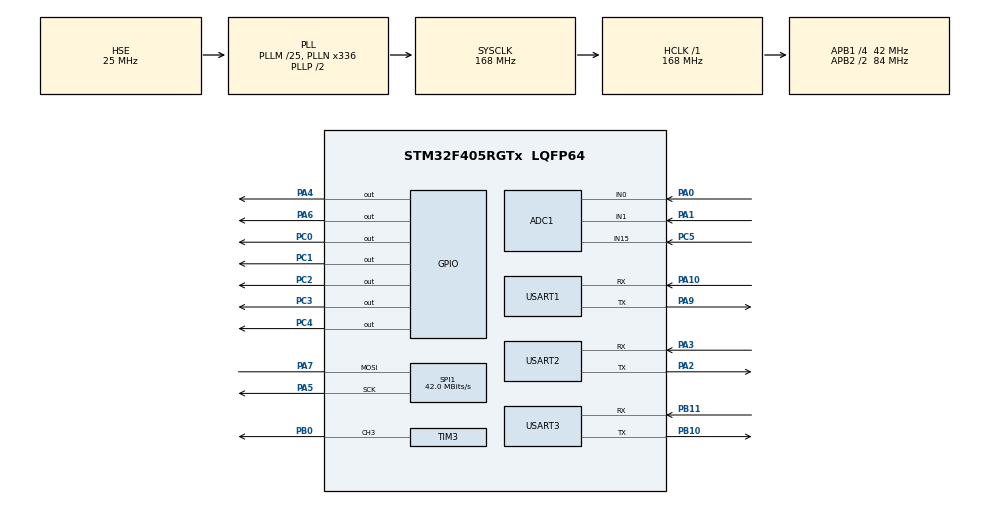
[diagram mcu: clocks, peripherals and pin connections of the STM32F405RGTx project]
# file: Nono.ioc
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ADC1.Channel-0\#ChannelRegularConversion=ADC_CHANNEL_0
ADC1.Channel-10\#ChannelRegularConversion=ADC_CHANNEL_TEMPSENSOR
ADC1.Channel-8\#ChannelRegularConversion=ADC_CHANNEL_1
ADC1.Channel-9\#ChannelRegularConversion=ADC_CHANNEL_15
ADC1.DataAlign=ADC_DATAALIGN_RIGHT
ADC1.InjNumberOfConversion=0
ADC1.NbrOfConversion=4
ADC1.NbrOfConversionFlag=1
ADC1.Rank-0\#ChannelRegularConversion=1
ADC1.Rank-10\#ChannelRegularConversion=4
ADC1.Rank-8\#ChannelRegularConversion=2
ADC1.Rank-9\#ChannelRegularConversion=3
ADC1.SamplingTime-0\#ChannelRegularConversion=ADC_SAMPLETIME_3CYCLES
ADC1.SamplingTime-10\#ChannelRegularConversion=ADC_SAMPLETIME_3CYCLES
ADC1.SamplingTime-8\#ChannelRegularConversion=ADC_SAMPLETIME_3CYCLES
ADC1.SamplingTime-9\#ChannelRegularConversion=ADC_SAMPLETIME_3CYCLES
ADC1.master=1
Dma.ADC1.0.Direction=DMA_PERIPH_TO_MEMORY
Dma.ADC1.0.FIFOMode=DMA_FIFOMODE_DISABLE
Dma.ADC1.0.Instance=DMA2_Stream0
Dma.ADC1.0.MemDataAlignment=DMA_MDATAALIGN_HALFWORD
Dma.ADC1.0.MemInc=DMA_MINC_ENABLE
Dma.ADC1.0.Mode=DMA_NORMAL
Dma.ADC1.0.PeriphDataAlignment=DMA_PDATAALIGN_HALFWORD
Dma.ADC1.0.PeriphInc=DMA_PINC_DISABLE
Dma.ADC1.0.Priority=DMA_PRIORITY_LOW
Dma.Request0=ADC1
FREERTOS.Tasks01=Main,40,256,StartMainTask,Default,NULL,Dynamic,NULL,NULL;LED,24,128,StartLED,Default,NULL,Dynamic,NULL,NULL
Mcu.Family=STM32F4
Mcu.Name=STM32F405RGTx
Mcu.Package=LQFP64
NVIC.DMA2_Stream0_IRQn=true\:5\:0\:false\:false\:true\:true\:false\:true\:true
NVIC.PriorityGroup=NVIC_PRIORITYGROUP_4
NVIC.TIM1_UP_TIM10_IRQn=true\:15\:0\:false\:false\:true\:false\:false\:true\:true
NVIC.TimeBase=TIM1_UP_TIM10_IRQn
NVIC.TimeBaseIP=TIM1
NVIC.USART1_IRQn=true\:5\:0\:false\:false\:true\:true\:true\:true\:true
NVIC.USART2_IRQn=true\:5\:0\:false\:false\:true\:true\:true\:true\:true
NVIC.USART3_IRQn=true\:5\:0\:false\:false\:true\:true\:true\:true\:true
PA0-WKUP.Signal=ADCx_IN0
PA1.Signal=ADCx_IN1
PA10.Mode=Asynchronous
PA10.Signal=USART1_RX
PA13.Mode=Serial_Wire
PA13.Signal=SYS_JTMS-SWDIO
PA14.Mode=Serial_Wire
PA14.Signal=SYS_JTCK-SWCLK
PA2.Mode=Asynchronous
PA2.Signal=USART2_TX
PA3.Mode=Asynchronous
PA3.Signal=USART2_RX
PA4.Signal=GPIO_Output
PA5.Mode=Simplex_Bidirectional_Master
PA5.Signal=SPI1_SCK
PA6.Signal=GPIO_Output
PA7.Mode=Simplex_Bidirectional_Master
PA7.Signal=SPI1_MOSI
PA9.Mode=Asynchronous
PA9.Signal=USART1_TX
PB0.Signal=S_TIM3_CH3
PB10.Mode=Asynchronous
PB10.Signal=USART3_TX
PB11.Mode=Asynchronous
PB11.Signal=USART3_RX
PC0.Signal=GPIO_Output
PC1.Signal=GPIO_Output
PC2.Signal=GPIO_Output
PC3.Signal=GPIO_Output
PC4.Signal=GPIO_Output
PC5.Signal=ADCx_IN15
PH0-OSC_IN.Mode=HSE-External-Oscillator
PH0-OSC_IN.Signal=RCC_OSC_IN
PH1-OSC_OUT.Mode=HSE-External-Oscillator
PH1-OSC_OUT.Signal=RCC_OSC_OUT
ProjectManager.HeapSize=0x1200
ProjectManager.StackSize=0x1200
ProjectManager.TargetToolchain=MDK-ARM V5.32
RCC.48MHZClocksFreq_Value=84000000
RCC.AHBFreq_Value=168000000
RCC.APB1CLKDivider=RCC_HCLK_DIV4
RCC.APB1Freq_Value=42000000
RCC.APB1TimFreq_Value=84000000
RCC.APB2CLKDivider=RCC_HCLK_DIV2
RCC.APB2Freq_Value=84000000
RCC.APB2TimFreq_Value=168000000
RCC.CortexFreq_Value=168000000
RCC.HCLKFreq_Value=168000000
RCC.HSE_VALUE=25000000
RCC.HSI_VALUE=16000000
RCC.LSE_VALUE=32768
RCC.PLLM=25
RCC.PLLN=336
RCC.PLLSourceVirtual=RCC_PLLSOURCE_HSE
RCC.RCC_RTC_Clock_Source=RCC_RTCCLKSOURCE_HSE_DIV25
RCC.RCC_RTC_Clock_SourceVirtual=RCC_RTCCLKSOURCE_LSE
RCC.RCC_RTC_Clock_Source_FROM_HSE=RCC_RTCCLKSOURCE_HSE_DIV25
RCC.SYSCLKFreq_VALUE=168000000
RCC.SYSCLKSource=RCC_SYSCLKSOURCE_PLLCLK
RCC.VCOOutputFreq_Value=336000000
RTC.AsynchPrediv=100
RTC.Date=20
RTC.Hours=14
RTC.Minutes=30
RTC.SynchPrediv=10000
RTC.Year=25
SH.ADCx_IN0.0=ADC1_IN0,IN0
SH.ADCx_IN1.0=ADC1_IN1,IN1
SH.ADCx_IN15.0=ADC1_IN15,IN15
SH.S_TIM3_CH3.0=TIM3_CH3,PWM Generation3 CH3
SPI1.CalculateBaudRate=42.0 MBits/s
SPI1.Direction=SPI_DIRECTION_1LINE
SPI1.Mode=SPI_MODE_MASTER
SPI1.VirtualType=VM_MASTER
TIM3.Channel-PWM\ Generation3\ CH3=TIM_CHANNEL_3
TIM3.Period=100-1
TIM3.Prescaler=8400-1
USART1.VirtualMode=VM_ASYNC
USART2.VirtualMode=VM_ASYNC
USART3.VirtualMode=VM_ASYNC
VP_ADC1_TempSens_Input.Mode=IN-TempSens
VP_FREERTOS_VS_CMSIS_V2.Mode=CMSIS_V2
VP_RTC_VS_RTC_Activate.Mode=RTC_Enabled
VP_RTC_VS_RTC_Calendar.Mode=RTC_Calendar
VP_SYS_VS_tim1.Mode=TIM1
VP_TIM3_VS_ClockSourceINT.Mode=Internal
board=custom

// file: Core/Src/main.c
/* USER CODE BEGIN Header */
/**
 ******************************************************************************
 * @file           : main.c
 * @brief          : Main program body
 ******************************************************************************
 * @attention
 *
 * Copyright (c) 2025 STMicroelectronics.
 * All rights reserved.
 *
 * This software is licensed under terms that can be found in the LICENSE file
 * in the root directory of this software component.
 * If no LICENSE file comes with this software, it is provided AS-IS.
 *
 ******************************************************************************
 */
/* USER CODE END Header */
#include "main.h"
#include "cmsis_os.h"
#include "adc.h"
#include "dma.h"
#include "rtc.h"
#include "spi.h"
#include "tim.h"
#include "usart.h"
#include "gpio.h"

/* USER CODE BEGIN Includes */

#include "general_control.h"
#include "sensor.h"
/* USER CODE END Includes */

void SystemClock_Config(void);
void MX_FREERTOS_Init(void);

int main(void)
{

  /* MCU Configuration--------------------------------------------------------*/

  /* Reset of all peripherals, Initializes the Flash interface and the Systick. */
  HAL_Init();

  /* Configure the system clock */
  SystemClock_Config();

  /* Initialize all configured peripherals */
  MX_GPIO_Init();
  MX_DMA_Init();
  MX_ADC1_Init();
  MX_SPI1_Init();
  MX_TIM3_Init();
  MX_USART1_UART_Init();
  MX_RTC_Init();
  MX_USART2_UART_Init();
  MX_USART3_UART_Init();
  /* USER CODE BEGIN 2 */
  ALL_Init();
  /* USER CODE END 2 */

  /* Init scheduler */
  osKernelInitialize();

  /* Call init function for freertos objects (in cmsis_os2.c) */
  MX_FREERTOS_Init();

  /* Start scheduler */
  osKernelStart();

  /* We should never get here as control is now taken by the scheduler */

  /* Infinite loop */
  while (1)
  {

  }
}

void SystemClock_Config(void)
{
  RCC_OscInitTypeDef RCC_OscInitStruct = {0};
  RCC_ClkInitTypeDef RCC_ClkInitStruct = {0};

  /** Configure the main internal regulator output voltage
  */
  __HAL_RCC_PWR_CLK_ENABLE();
  __HAL_PWR_VOLTAGESCALING_CONFIG(PWR_REGULATOR_VOLTAGE_SCALE1);

  /** Initializes the RCC Oscillators according to the specified parameters
  * in the RCC_OscInitTypeDef structure.
  */
  RCC_OscInitStruct.OscillatorType = RCC_OSCILLATORTYPE_HSE;
  RCC_OscInitStruct.HSEState = RCC_HSE_ON;
  RCC_OscInitStruct.PLL.PLLState = RCC_PLL_ON;
  RCC_OscInitStruct.PLL.PLLSource = RCC_PLLSOURCE_HSE;
  RCC_OscInitStruct.PLL.PLLM = 25;
  RCC_OscInitStruct.PLL.PLLN = 336;
  RCC_OscInitStruct.PLL.PLLP = RCC_PLLP_DIV2;
  RCC_OscInitStruct.PLL.PLLQ = 4;
  if (HAL_RCC_OscConfig(&RCC_OscInitStruct) != HAL_OK)
  {
    Error_Handler();
  }

  /** Initializes the CPU, AHB and APB buses clocks
  */
  RCC_ClkInitStruct.ClockType = RCC_CLOCKTYPE_HCLK|RCC_CLOCKTYPE_SYSCLK
                              |RCC_CLOCKTYPE_PCLK1|RCC_CLOCKTYPE_PCLK2;
  RCC_ClkInitStruct.SYSCLKSource = RCC_SYSCLKSOURCE_PLLCLK;
  RCC_ClkInitStruct.AHBCLKDivider = RCC_SYSCLK_DIV1;
  RCC_ClkInitStruct.APB1CLKDivider = RCC_HCLK_DIV4;
  RCC_ClkInitStruct.APB2CLKDivider = RCC_HCLK_DIV2;

  if (HAL_RCC_ClockConfig(&RCC_ClkInitStruct, FLASH_LATENCY_5) != HAL_OK)
  {
    Error_Handler();
  }
}

void HAL_TIM_PeriodElapsedCallback(TIM_HandleTypeDef *htim)
{
  if (htim->Instance == TIM1)
  {
    HAL_IncTick();
  }
}

void Error_Handler(void)
{
  /* USER CODE BEGIN Error_Handler_Debug */
  /* User can add his own implementation to report the HAL error return state */
  __disable_irq();
  while (1)
  {
    HAL_GPIO_WritePin(GPIOC, GPIO_PIN_0, GPIO_PIN_SET);
    HAL_Delay(100);
    HAL_GPIO_WritePin(GPIOC, GPIO_PIN_0, GPIO_PIN_SET);
    HAL_Delay(100);
  }
  /* USER CODE END Error_Handler_Debug */
}

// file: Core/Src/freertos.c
/* USER CODE BEGIN Header */
/**
  ******************************************************************************
  * File Name          : freertos.c
  * Description        : Code for freertos applications
  ******************************************************************************
  * @attention
  *
  * Copyright (c) 2025 STMicroelectronics.
  * All rights reserved.
  *
  * This software is licensed under terms that can be found in the LICENSE file
  * in the root directory of this software component.
  * If no LICENSE file comes with this software, it is provided AS-IS.
  *
  ******************************************************************************
  */
/* USER CODE END Header */

#include "FreeRTOS.h"
#include "task.h"
#include "main.h"
#include "cmsis_os.h"

/* USER CODE BEGIN Includes */
#include "general_control.h"
#include "LED.h"
#include "expression.h"
#include "tim.h"
#include "sensor.h"
/* USER CODE END Includes */

/* Definitions for Main */
osThreadId_t MainHandle;
const osThreadAttr_t Main_attributes = {
  .name = "Main",
  .stack_size = 256 * 4,
  .priority = (osPriority_t) osPriorityHigh,
};
/* Definitions for LED */
osThreadId_t LEDHandle;
const osThreadAttr_t LED_attributes = {
  .name = "LED",
  .stack_size = 128 * 4,
  .priority = (osPriority_t) osPriorityNormal,
};

void StartMainTask(void *argument);
void StartLED(void *argument);

void MX_FREERTOS_Init(void); /* (MISRA C 2004 rule 8.1) */

void MX_FREERTOS_Init(void) {

  /* Create the thread(s) */
  /* creation of Main */
  MainHandle = osThreadNew(StartMainTask, NULL, &Main_attributes);

  /* creation of LED */
  LEDHandle = osThreadNew(StartLED, NULL, &LED_attributes);

}

void StartMainTask(void *argument)
{
  /* USER CODE BEGIN StartMainTask */
  /* Infinite loop */
  for(;;)
  {
    //	clock_run_second(64);
    //  clock_run_time(64);
    EYE_BLINK(GRAYBLUE, 10);
		Sensor_show_power_temp();
  }
  /* USER CODE END StartMainTask */
}

void StartLED(void *argument)
{
  /* USER CODE BEGIN StartLED */
  /* Infinite loop */
  for(;;)
  {
//    LED_run();
  }
  /* USER CODE END StartLED */
}
